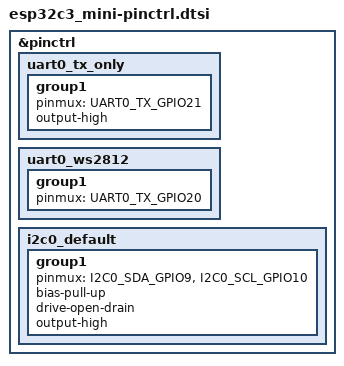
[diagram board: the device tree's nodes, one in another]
/*
 * Copyright (c) 2024 Arrel Neumiller
 * SPDX-License-Identifier: Apache-2.0
 */

#include <zephyr/dt-bindings/pinctrl/esp32c3-pinctrl.h>

&pinctrl {
	uart0_tx_only: uart0_tx_only {
		group1 {
			pinmux = <UART0_TX_GPIO21>;
			output-high;
		};
	};

	uart0_ws2812: uart0_ws2812 {
		group1 {
			pinmux = <UART0_TX_GPIO20>;
		};
	};

	i2c0_default: i2c0_default {
		group1 {
			pinmux = <I2C0_SDA_GPIO9>,
				 <I2C0_SCL_GPIO10>;
			bias-pull-up;
			drive-open-drain;
			output-high;
		};
	};
};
